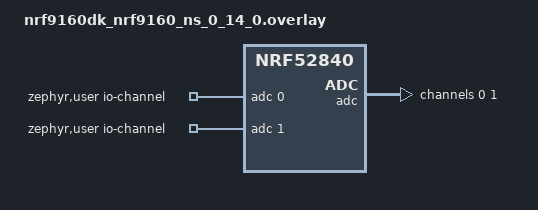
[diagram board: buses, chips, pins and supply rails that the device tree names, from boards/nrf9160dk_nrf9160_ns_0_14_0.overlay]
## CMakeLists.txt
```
#
# Copyright (c) 2018 Nordic Semiconductor
#
# SPDX-License-Identifier: LicenseRef-Nordic-5-Clause
#

cmake_minimum_required(VERSION 3.20.0)

find_package(Zephyr REQUIRED HINTS $ENV{ZEPHYR_BASE})
project(lte_ble_gateway_1)

# NORDIC SDK APP START
target_sources(app PRIVATE src/main.c)
# NORDIC SDK APP END
zephyr_include_directories(src)

include_directories(src/orientation_detector)

# zephyr_include_directories(cJSON)
# zephyr_library_sources(cJSON/cJSON.c)
```

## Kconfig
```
#
# Copyright (c) 2018 Nordic Semiconductor ASA
#
# SPDX-License-Identifier: LicenseRef-Nordic-5-Clause
#

menu "LTE BLE gateway sample"

config MQTT_BROKER_HOSTNAME
	string "MQTT broker hostname"
	default "custom.url"
config MQTT_DEVICE_ID
	string "MQTT device ID"
	default "nrf9160dk_board_1"
config MQTT_USERNAME
	string "MQTT username"
	default "mqtt_user"
config MQTT_PASSWORD
	string "MQTT password"
	default "mqtt_password"
config MQTT_PORT
	int "MQTT port"
	default 8883
config MQTT_TOPIC
	string "MQTT topic"
	default "#"
config MQTT_CONNECT_TIMEOUT
	int "MQTT connect timeout"
	default 10000
config MQTT_KEEPALIVE
	int "MQTT keepalive"
	default 30

config UDP_SERVER_ADDRESS_STATIC
	string "UDP server IP address"
	default "custom udp address"

config UDP_SERVER_PORT
	string "UDP server IP address"
	default "5005"

config GNSS_SEARCH_INTERVAL
	int "Interval for starting GNSS search"
	default 240

config GNSS_SEARCH_TIMEOUT
	int "Timeout for GNSS search"
	default 120
	help
	  The GNSS will stop acquiring GNSS fix when it times out.
	  It will restart the search at the start of the next search interval.

endmenu

module=LTE_BLE_GW
module-dep=LOG
module-str= LTE BLE gateway sample
source "${ZEPHYR_BASE}/subsys/logging/Kconfig.template.log_config"

menu "Zephyr Kernel"
source "Kconfig.zephyr"
endmenu
```

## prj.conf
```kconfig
#
# Copyright (c) 2019 Nordic Semiconductor ASA
#
# SPDX-License-Identifier: LicenseRef-Nordic-5-Clause
#
# General config
CONFIG_ASSERT=y
CONFIG_REBOOT=y

# Network
CONFIG_NETWORKING=y
CONFIG_NET_NATIVE=n
CONFIG_NET_SOCKETS=y
CONFIG_NET_SOCKETS_OFFLOAD=y
CONFIG_NET_IPV4=y
CONFIG_NET_TCP=y


CONFIG_HTTP_CLIENT=y

#CONFIG_LTE_NETWORK_MODE_NBIOT=y
#CONFIG_LTE_NETWORK_MODE_LTE_M=n
CONFIG_LTE_NETWORK_MODE_LTE_M_NBIOT_GPS=y

# LTE link control
CONFIG_LTE_LINK_CONTROL=y
CONFIG_LTE_LC_PSM_MODULE=y


# AT host
CONFIG_AT_HOST_LIBRARY=y

# Modem library
CONFIG_NRF_MODEM_LIB=y
# Modem library fault handling
CONFIG_NRF_MODEM_LIB_ON_FAULT_APPLICATION_SPECIFIC=y



# # nRF Cloud
CONFIG_NRF_CLOUD_MQTT=y
# CONFIG_NRF_CLOUD_AGNSS=y

# Modem info
CONFIG_MODEM_INFO=y
CONFIG_MODEM_INFO_ADD_NETWORK=y

# Logging
CONFIG_LOG=y
# CONFIG_NET_LOG=y
# CONFIG_MQTT_LOG_LEVEL_DBG=y
# CONFIG_LTE_BLE_GW_LOG_LEVEL_INF=y

# For demo purposes, we acquire fix often
CONFIG_GNSS_SEARCH_INTERVAL=30
CONFIG_GNSS_SEARCH_TIMEOUT=15

# Console for user association
CONFIG_CONSOLE_SUBSYS=y
CONFIG_CONSOLE_GETCHAR=y

CONFIG_UART_INTERRUPT_DRIVEN=y

# Heap and stacks
CONFIG_HEAP_MEM_POOL_SIZE=16384
CONFIG_MAIN_STACK_SIZE=16384
CONFIG_SYSTEM_WORKQUEUE_STACK_SIZE=4096

CONFIG_NET_SOCKETS_POSIX_NAMES=y

CONFIG_MQTT_LIB=y

# CONFIG_LOG_DEFAULT_LEVEL=4
# CONFIG_MQTT_LOG_LEVEL_DEFAULT=y

#CONFIG_MQTT_HELPER=y
CONFIG_CJSON_LIB=y

CONFIG_NEWLIB_LIBC=y
CONFIG_NEWLIB_LIBC_FLOAT_PRINTF=y
CONFIG_NEWLIB_LIBC_FLOAT_SCANF=y

CONFIG_DK_LIBRARY=y

CONFIG_DATE_TIME=y

CONFIG_POSIX_API=y
CONFIG_POSIX_TIMERS=y
CONFIG_POSIX_CLOCK=y

CONFIG_CBPRINTF_FP_SUPPORT=y

# Disable Modem traces, since we need UART1 for HCI
CONFIG_NRF_MODEM_LIB_TRACE=n


CONFIG_MODEM_KEY_MGMT=y
CONFIG_MQTT_LIB_TLS=y
CONFIG_TLS_CREDENTIALS=y

CONFIG_ADC=y
CONFIG_HWINFO=y

CONFIG_LTE_LC_CONN_EVAL_MODULE=y
CONFIG_MODEM_INFO=y

CONFIG_LTE_LC_EDRX_MODULE=y


CONFIG_TRACING=y
CONFIG_PM=y
CONFIG_PM_DEVICE=y

CONFIG_NRF_MODEM_LIB_TRACE_BACKEND_UART=y

CONFIG_LOG_BACKEND_SHOW_COLOR=n

CONFIG_GNSS_SEARCH_INTERVAL=30
CONFIG_GNSS_SEARCH_TIMEOUT=15
CONFIG_SUPL_CLIENT_LIB=y
```

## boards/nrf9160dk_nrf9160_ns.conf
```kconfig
CONFIG_NRF_SW_LPUART=n
CONFIG_NRF_SW_LPUART_INT_DRIVEN=n

CONFIG_UART_2_ASYNC=y
CONFIG_UART_2_INTERRUPT_DRIVEN=n
CONFIG_UART_2_NRF_HW_ASYNC=y
CONFIG_UART_2_NRF_HW_ASYNC_TIMER=2

#CONFIG_MQTT_HELPER_SEC_TAG=955
```

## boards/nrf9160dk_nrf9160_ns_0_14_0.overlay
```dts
/* Use the reset line that is available starting from v0.14.0 of the DK. */
#include <nrf9160/nrf9160dk_nrf52840_reset_on_if9.dtsi>

/ {
	zephyr,user {
		io-channels = <&adc 0>, <&adc 1>;
	};
};

&adc {
	#address-cells = <1>;
	#size-cells = <0>;

	channel@0 {
		reg = <0>;
		zephyr,gain = "ADC_GAIN_1_4";
		zephyr,reference = "ADC_REF_INTERNAL";
		zephyr,acquisition-time = <ADC_ACQ_TIME_DEFAULT>;
		zephyr,input-positive = <NRF_SAADC_AIN1>;
		zephyr,resolution = <12>;
	};

	channel@1 {
		reg = <1>;
		zephyr,gain = "ADC_GAIN_1_6";
		zephyr,reference = "ADC_REF_INTERNAL";
		zephyr,acquisition-time = <ADC_ACQ_TIME_DEFAULT>;
		zephyr,input-positive = <NRF_SAADC_AIN2>; 
		zephyr,resolution = <14>;
		zephyr,oversampling = <8>;
	};
};
```

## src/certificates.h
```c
/*
 * Copyright (c) 2020 Nordic Semiconductor ASA
 *
 * SPDX-License-Identifier: LicenseRef-Nordic-5-Clause
 */
/** CA certificate for mqtt.eclipseprojects.io, Let’s Encrypt R3 */
	

#define CA_CERTIFICATE "-----BEGIN CERTIFICATE-----\n" \
"-----END CERTIFICATE-----\n"
```
